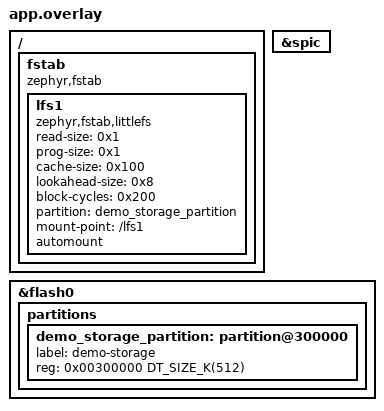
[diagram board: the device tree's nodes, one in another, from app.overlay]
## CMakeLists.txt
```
# Copyright (c) 2024 Realtek Semiconductor Corp.
# SPDX-License-Identifier: Apache-2.0

cmake_minimum_required(VERSION 3.20.0)

set(CMAKE_C_FLAGS "${CMAKE_C_FLAGS} -save-temps=obj")

find_package(Zephyr REQUIRED HINTS $ENV{ZEPHYR_BASE})
project(littlefs)

target_sources(app PRIVATE src/main.c)
```

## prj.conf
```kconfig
# 启用随机数生成器
CONFIG_TEST_RANDOM_GENERATOR=y

# LittleFS 配置
CONFIG_FILE_SYSTEM=y
CONFIG_FILE_SYSTEM_LITTLEFS=y

# 启用擦除信息统计（可选）
# CONFIG_FS_LITTLEFS_ENABLE_BLOCK_STATISTICS=y

# Flash 分区配置（根据你的设备调整）
# MUST set CONFIG_FLASH and CONFIG_FLASH_MAP manually, otherwise CONFIG_FS_LITTLEFS_FMP_DEV is not set
CONFIG_FLASH=y
CONFIG_FLASH_MAP=y
# CONFIG_FLASH_PAGE_LAYOUT=y

# 堆栈和内存配置
CONFIG_MAIN_STACK_SIZE=4096
CONFIG_HEAP_MEM_POOL_SIZE=8192

# 调试输出
# CONFIG_DEBUG=y
CONFIG_LOG=y
CONFIG_LOG_MODE_MINIMAL=y
# CONFIG_FS_LOG_LEVEL_INF=y
```

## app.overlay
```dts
/*
 * Copyright (c) 2022 Nordic Semiconductor ASA
 *
 * SPDX-License-Identifier: Apache-2.0
 */

&spic {
	status = "okay";
};

/*
&storage_partition {
  reg = <0x00250000 DT_SIZE_K(256)>;
};
*/

&flash0 {
  partitions {
    demo_storage_partition: partition@300000 {
      label = "demo-storage";
      reg = <0x00300000 DT_SIZE_K(512)>;
    };
  };
};

/ {
  fstab {
    compatible = "zephyr,fstab";
    lfs1: lfs1 {
      compatible = "zephyr,fstab,littlefs";
      read-size = < 0x1 >;
      prog-size = < 0x1 >;
      cache-size = < 0x100 >;
      lookahead-size = < 0x8 >;
      block-cycles = < 0x200 >;
      partition = <&demo_storage_partition>;
      mount-point = "/lfs1";
      automount;
    };
  };
};
```

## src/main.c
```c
/*
 * LittleFS on NOR Flash 性能测试代码
 */
#include "ameba_soc.h"

#include <zephyr/kernel.h>
#include <zephyr/fs/fs.h>
#include <zephyr/fs/littlefs.h>
#include <zephyr/storage/flash_map.h>
#include <zephyr/sys/printk.h>
#include <zephyr/random/random.h>
#include <zephyr/sys/time_units.h>
#include <string.h>
#include <stdlib.h>

/* 测试配置 */
#define TEST_PARTITION        demo_storage_partition  /* Flash 分区标签 */
#define TEST_MOUNT_POINT      "/lfs1"

#define SYNC_AFTER_WRITE (1)

#define TEST_BLOCK_SIZE_MAX     (32*1024)           /* fs_read|write API 单次读|写的 最大大小 */
#define TEST_FILE_NAME      "/lfs1/test.bin"
#define TEST_ITERATIONS     (10)

#define CHECK_READ_DATA (0) //  是否检查读出数据的有效性
#define RW_DATA_PATTREN_BASE (0xA0)
static unsigned char grw_data_pattern = 0xA0;

// 随机写的时候，速度可能小于1，而 printk 不支持打印浮点，所以放大显示
#define WRITE_SPEED_MULTIPLIER (100)

struct fs_test_config {
    uint32_t file_size_bytes;   // total file size
    uint32_t block_size_bytes;  // read/write size each time
    bool random_access;
    uint32_t rows;  // random matrix row
    uint32_t cols;  // random matrix columns

    uint32_t avg_write_speed;
    uint32_t avg_read_speed;
    uint32_t read_success_rate_x100;
    uint32_t write_success_rate_x100;
};

/* 性能统计结构体 */
struct perf_stats {
    struct fs_test_config *config;

    // 开始时，用 ms 计时，但读速度过快，ms级别精度不够，所有换成了us
    // 可以移除 ms 级别的计时
    uint64_t write_time_ms;
    uint64_t read_time_ms;

    // 最终使用的是 us 级别的计时
    uint64_t read_time_cycles;
    uint64_t write_time_cycles;
    uint64_t read_time_us;      // cycles -> us 换算得
    uint64_t write_time_us;     // cycles -> us 换算得

    uint32_t write_speed_kbps;
    uint32_t read_speed_kbps;
    uint32_t written_bytes;
    uint32_t read_bytes;

    uint32_t write_operations_completed;
    uint32_t read_operations_completed;

    bool read_success;  // true: 每次都读成功
    bool write_success; // true: 每次都写成功了
};

static uint8_t buffer[TEST_BLOCK_SIZE_MAX] __attribute__((aligned(4096)));
#if CHECK_READ_DATA
static uint8_t expected_buffer[TEST_BLOCK_SIZE_MAX];
#endif


static const uint32_t file_lengths[] = {
    4*1024,
    8*1024,
    16*1024,
    32*1024,
    64*1024,

    /* 文件 128KB时， app.overlay 中的 partition 需要 512KB, 否则随机读容易失败 */
    // 128*1024,
    };

static const uint32_t block_lengths[] = {
    128,
    256,
    512,
    1024,
    2*1024,
    4*1024,
    8*1024,
    16*1024
};

/* 全局统计 */
static struct perf_stats stats[TEST_ITERATIONS];

FS_LITTLEFS_DECLARE_DEFAULT_CONFIG(storage);
static struct fs_mount_t lfs_storage_mnt = {
    .type = FS_LITTLEFS,
    .fs_data = &storage,
    .storage_dev = (void *)FIXED_PARTITION_ID(TEST_PARTITION),
    .mnt_point = TEST_MOUNT_POINT,
};

/******************************************************************/
/******************************************************************/
#define RANDOM_COL_RANGE (1024)
#define RANDOM_ROW_RANGE (64)

// 全局变量：随机排列
uint8_t randrows[RANDOM_ROW_RANGE];  // 行的随机排列
uint16_t randcols[RANDOM_COL_RANGE];  // 列的随机排列

// 初始化随机排列
void RandomPermutationsInitialize(int M, int N) {
    if (M > RANDOM_ROW_RANGE || N > RANDOM_COL_RANGE) {
        printf("error: random row %d > %d, col %d > %d\n",
            M, RANDOM_ROW_RANGE, N, RANDOM_COL_RANGE);
        return;
    }

    // 初始化randrows数组为0到M-1
    for (int i = 0; i < M; i++) {
        randrows[i] = i;
    }
    
    // 初始化randcols数组为0到N-1
    for (int j = 0; j < N; j++) {
        randcols[j] = j;
    }
    
    // 打乱randrows数组 (Fisher-Yates洗牌算法)
    for (int i = M - 1; i > 0; i--) {
        int j = sys_rand32_get() % (i + 1);
        // 交换randrows[i]和randrows[j]
        int temp = randrows[i];
        randrows[i] = randrows[j];
        randrows[j] = temp;
    }
    
    // 打乱randcols数组 (Fisher-Yates洗牌算法)
    for (int i = N - 1; i > 0; i--) {
        int j = sys_rand32_get() % (i + 1);
        // 交换randcols[i]和randcols[j]
        int temp = randcols[i];
        randcols[i] = randcols[j];
        randcols[j] = temp;
    }

#if 0
    // 打印随机排列
    printf("rand rows [%d]: ", M);
    for (int i = 0; i < M; i++) {
        printf("%d ", randrows[i]);
    }
    printf("\n");
    
    printf("rand columns [%d]: ", N);
    for (int j = 0; j < N; j++) {
        printf("%d ", randcols[j]);
    }
    printf("\n\n");
#endif

    DCache_Clean((uint32_t)randrows, sizeof(randrows[0])*M);
    DCache_Clean((uint32_t)randcols, sizeof(randcols[0])*N);
}

static uint32_t RandomPermutationsGet(uint32_t row, uint32_t col, uint32_t columns) {
    uint32_t value = randrows[row] * columns + randcols[col];
    return value;
}


/* 打印文件系统的使用情况 */
static void print_file_system_status() {
    struct fs_statvfs stats;
    int rc = fs_statvfs(lfs_storage_mnt.mnt_point, &stats);
    if (rc < 0) {
        LOG_PRINTK("FAIL: statvfs: %d\n", rc);
        return;
    }

    LOG_PRINTK("%s: bsize = %lu ; frsize = %lu ; blocks = %lu ; bfree = %lu;"
                "total size %lu KB, available size %lu KB, used %lu KB\n",
            lfs_storage_mnt.mnt_point,
            stats.f_bsize, stats.f_frsize, stats.f_blocks, stats.f_bfree,
           stats.f_frsize * stats.f_blocks / 1024,
           stats.f_frsize * stats.f_bfree / 1024,
           (stats.f_blocks - stats.f_bfree) *stats.f_frsize / 1024
           );
}

/* 生成测试数据 */
static void generate_test_data(uint8_t *buffer, size_t size, uint8_t pattern)
{
#if CHECK_READ_DATA
    for (size_t i = 0; i < size; i++) {
        buffer[i] = (pattern + i) & 0xFF;
    }
#else
    memset(buffer, pattern&0xFF, size);
#endif

    DCache_Clean((uint32_t)buffer, size);
}

/* 测试顺序写入 */
static int test_write(struct perf_stats *stat)
{
    int rc;
    struct fs_file_t file;
    int64_t start_time, end_time;
    uint64_t start_cycles, end_cycles;

    uint32_t block_size = stat->config->block_size_bytes;  // buffer_size
    uint32_t file_size = stat->config->file_size_bytes;
    uint32_t chunk_size = -1;    // chunk size read or write each time

    /* 打开文件用于写入 */
    fs_file_t_init(&file);
    rc = fs_open(&file, TEST_FILE_NAME, FS_O_CREATE | FS_O_WRITE);
    if (rc < 0) {
        printk("Failed to open file for writing: %d\n", rc);
        return rc;
    }
    
    /* 生成测试数据 */
    generate_test_data(buffer, block_size, grw_data_pattern);
    
    /* 开始计时 */
    start_time   = k_uptime_get();
    start_cycles = k_cycle_get_64();
    
    /* 写入 */
    size_t total_written = 0;
    uint32_t offset = -1;
    int row_start = 0;
    int row = 0;
    int col  = 0;
    // DiagPrintf("\n");
    while (total_written < file_size) {
        if (stat->config->random_access) {
            offset = RandomPermutationsGet(row, col, stat->config->cols);
            offset = offset * block_size;
            // DiagPrintf("w [%d][%d] %u\n", row, col, offset);

            rc = fs_seek(&file, offset, FS_SEEK_SET);
            if (rc < 0) {
                printk("Seek failed: %d, offset %d\n", rc, offset);
                break;
            }
            // printk("rand write at offset %u\n", offset);
        }

        chunk_size = (file_size - total_written < block_size) ? file_size - total_written : block_size;
        rc = fs_write(&file, buffer, chunk_size);
        if (rc < 0 ||  rc != chunk_size) {
            printk("Write failed: expected %d, written %d; at %d\n", chunk_size, rc, total_written);
            rc = -1;
            goto out;
        }

        total_written += rc;
        stat->write_operations_completed++;
        rc = 0;

        if (stat->config->random_access) {
            row = (row + 1)% stat->config->rows;
            col++;
            if (col == stat->config->cols) {
                row_start++;
                row = row_start;
                col = 0;
            }
        }

#if CHECK_READ_DATA
        if (stat->write_operations_completed == 1) {
            printk("%u, %u, %u, %u\n", buffer[0], buffer[4], buffer[8], buffer[12]);
        }
#endif

    }

    if (stat->config->random_access) {
        printk("last write offset %d, cur_pos %d\n", offset, offset + chunk_size);
    } 

#if SYNC_AFTER_WRITE
    fs_sync(&file);
#endif

out:
    if (total_written == file_size) {
        stat->write_success = true;
    } else {
        stat->write_success = false;
    }
    stat->written_bytes = total_written;

    /* 结束计时 */
    end_time   = k_uptime_get();
    end_cycles = k_cycle_get_64();
    
    /* 记录耗时 */
    stat->write_time_cycles = end_cycles - start_cycles;
    stat->write_time_ms = end_time - start_time;

    rc = fs_close(&file);
    if (rc != 0) {
        printk("Error closing file: %d\n", rc);
    }

    return rc;
}

/* 测试顺序读取 */
static int test_read(struct perf_stats *stat)
{
    int rc;
    struct fs_file_t file;
    int64_t start_time, end_time;
    uint64_t start_cycles, end_cycles;
    uint32_t block_size = stat->config->block_size_bytes;  // buffer_size
    uint32_t file_size = stat->config->file_size_bytes;
    uint32_t chunk_size;    // chunk size read or write each time
    
    /* 打开文件用于读取 */
    fs_file_t_init(&file);
    rc = fs_open(&file, TEST_FILE_NAME, FS_O_READ);
    if (rc < 0) {
        printk("Failed to open file for reading: %d\n", rc);
        return rc;
    }

#if CHECK_READ_DATA
    /* 生成预期数据 */
    generate_test_data(expected_buffer, block_size, grw_data_pattern);
#endif

    /* 开始计时 */
    start_time   = k_uptime_get();
    start_cycles = k_cycle_get_64();
    
    /* 读取并验证 */
    uint32_t offset;
    int row_start = 0;
    int row = 0;
    int col  = 0;
    size_t total_read = 0;
    while (total_read < file_size) {
        if (stat->config->random_access) {
            offset = RandomPermutationsGet(row, col, stat->config->cols);
            offset = offset * block_size;

            // DiagPrintf("r [%d] [%d] %u\n", row, col, offset);

            rc = fs_seek(&file, offset, FS_SEEK_SET);
            if (rc < 0) {
                printk("Seek failed: %d, offset %d\n", rc, offset);
                break;
            }
            // printk("rand read at offset %u\n", offset);
        }

        chunk_size = (file_size - total_read < block_size) ? file_size - total_read : block_size;
        rc = fs_read(&file, buffer, chunk_size);
        if (rc < 0 || rc != chunk_size) {
            printk("Read failed: expected %d, read %d; at %d\n", chunk_size, rc, total_read);
            rc = -1;
            goto out;
        }

        total_read += rc;
        stat->read_operations_completed++;

        if (stat->config->random_access) {
            row = (row + 1)% stat->config->rows;
            col++;
            if (col == stat->config->cols) {
                row_start++;
                row = row_start;
                col = 0;
            }
        }

#if CHECK_READ_DATA
if (stat->read_operations_completed == 1) {
            printk("%u, %u, %u, %u\n", buffer[0], buffer[4], buffer[8], buffer[12]);
        }

        /* 验证数据完整性 */
        if (memcmp(buffer, expected_buffer, rc) != 0) {
            printk("ERROR: Data verification failed at offset %zu\n", total_read);
            fs_close(&file);
            return -1;
        }
#endif


        rc = 0;
    }

out:
    if (total_read == file_size) {
        stat->read_success = true;
    } else {
        stat->read_success = false;
    }
    stat->read_bytes = total_read;

    /* 结束计时 */
    end_time   = k_uptime_get();
    end_cycles = k_cycle_get_64();
    
    /* 计算耗时*/
    stat->read_time_cycles = end_cycles - start_cycles;
    stat->read_time_ms = (end_time - start_time);

    fs_close(&file);
    return rc;
}

/* 显示性能结果 */
static void display_performance_results(struct fs_test_config *config, struct perf_stats *stats)
{
    printk("\n====== LittleFS Performance Results ======\n");
    printk("file_size %d bytes, block_size %d bytes, random access %d. "
            "Average read speed %d KB/s. Average write speed %u.%.2u KB/s. "
            "ReadSuccessRate %u%%, WriteSuccessRate %u%%\n", 
        config->file_size_bytes, config->block_size_bytes, config->random_access, 
        config->avg_read_speed, config->avg_write_speed / WRITE_SPEED_MULTIPLIER, config->avg_write_speed % WRITE_SPEED_MULTIPLIER,
        config->read_success_rate_x100, config->write_success_rate_x100);

    for (int i = 0; i < TEST_ITERATIONS; i++) {
        struct perf_stats *stat = &stats[i];
        printk("[%d] WriteSuccess %d, Completed Operations %u; ReadSuccess %d, Completed Operations %u\n",
            i, stat->write_success, stat->write_operations_completed, stat->read_success, stat->read_operations_completed);
        printk("[%d] Sequential Write: %llu ms, %llu us, %u.%.2u KB/s\n", 
            i, stat->write_time_ms, stat->write_time_us,
            stat->write_speed_kbps / WRITE_SPEED_MULTIPLIER, stat->write_speed_kbps % WRITE_SPEED_MULTIPLIER);
        printk("[%d] Sequential Read:  %llu ms, %llu us, %u KB/s.\n", 
            i, stat->read_time_ms, stat->read_time_us, stat->read_speed_kbps);

    }
    printk("======================================\n\n");
}

/* 主测试函数 */
int main(void) {
    int rc;
    printk("\n***** LittleFS on NOR Flash Performance Test *****\n");
    uint64_t cycles_per_sec = sys_clock_hw_cycles_per_sec();
    printk("cycles_per_sec=%llu\n", cycles_per_sec);

    print_file_system_status();

    // 清理测试文件，确保测试环境重置
    (void)fs_unlink(TEST_FILE_NAME);

    print_file_system_status();

    int total_cases = 2*ARRAY_SIZE(block_lengths)*ARRAY_SIZE(file_lengths);
    int case_number = 0;
    struct fs_test_config test_config;
    for (int random = 0; random < 2; random++) {
        for (size_t block = 0; block < ARRAY_SIZE(block_lengths); block++) {
            for (size_t flen = 0; flen < ARRAY_SIZE(file_lengths); flen++) {
                // 设置测试参数
                memset(&test_config, 0, sizeof(struct fs_test_config));
                test_config.file_size_bytes =  file_lengths[flen];
                test_config.block_size_bytes = block_lengths[block];
                test_config.random_access = random;
                case_number++;

                struct fs_test_config *config = &test_config;
                if ((config->block_size_bytes > config->file_size_bytes) 
                    // || (config->random_access && config->file_size_bytes > 16*1024)

                    /* fs_write len 很小时，随机写的速度很慢，跳过*/
                    || (config->random_access && config->block_size_bytes < 512
                    )
                    ) {
                    printk("skip: [%d:%d] file %u bytes, block %u bytes, random access %d\n",
                        case_number, total_cases,
                        config->file_size_bytes, config->block_size_bytes, config->random_access);
                    continue;
                }

                if (config->block_size_bytes > TEST_BLOCK_SIZE_MAX) {
                    printk("ERROR: block_size %d exceeds %d\n", config->block_size_bytes, TEST_BLOCK_SIZE_MAX);
                    continue;
                }

                printk("test: [%d:%d] file %d bytes, block %d bytes, random access %d\n", 
                    case_number, total_cases,
                    config->file_size_bytes, config->block_size_bytes, config->random_access);

                /* 预生成 随机序列 */
                int blocks = config->file_size_bytes/config->block_size_bytes;
                if (blocks > RANDOM_COL_RANGE) {
                    config->cols = RANDOM_COL_RANGE;
                    config->rows = blocks/RANDOM_COL_RANGE;
                } else {
                    config->rows = 1;
                    config->cols = blocks;
                }
                if (config->rows * config->cols != blocks || config->rows > RANDOM_ROW_RANGE) {
                    printk("ERROR: rows %d, cols %d, blocks %d\n", config->rows, config->cols, blocks);
                    continue;
                }

                RandomPermutationsInitialize(config->rows, config->cols);

                memset(stats, 0, sizeof(stats[0]) * TEST_ITERATIONS);
                for (int i = 0; i < TEST_ITERATIONS; i++) {
                    grw_data_pattern = RW_DATA_PATTREN_BASE + i;
                    (void)fs_unlink(TEST_FILE_NAME);
                    struct perf_stats *stat = &stats[i];
                    stat->config = config;

                    printk("iteration: %d:%d\n", i, TEST_ITERATIONS);
                    /* 测试1: 顺序写入 */
                    // print_file_system_status();
                    printk("Test 1: write test...\n");
                    DCache_CleanInvalidate(0xFFFFFFFF, 0xFFFFFFFF);
                    rc = test_write(stat);
                    if (rc != 0) {
                        printk("[%d] Sequential write test failed: %d\n", i, rc);
                        // return rc;
                    }

                    /* 测试2: 顺序读取 */
                    // print_file_system_status();
                    printk("Test 2: read test...\n");
                    DCache_CleanInvalidate(0xFFFFFFFF, 0xFFFFFFFF);
                    rc = test_read(stat);
                    if (rc != 0) {
                        printk("[%d] Sequential read test failed: %d\n", i, rc);
                        // return rc;
                    }
                }

                /* 计算均值, 只有成功的 iteration 参与均值计算，
                    以防在 pos=0 处失败时，read_bytes或written_bytes 为0，导致计算的速度为0*/
                uint32_t total_read_speed = 0;
                uint32_t total_write_speed = 0;
                uint32_t read_success_times = 0;
                uint32_t write_success_times = 0;
                for (int i = 0; i < TEST_ITERATIONS; i++) {
                    struct perf_stats *stat = &stats[i];

                    stat->read_time_us = (stat->read_time_cycles * 1000000ULL) / cycles_per_sec;
                    stat->write_time_us = (stat->write_time_cycles * 1000000ULL) / cycles_per_sec;
                    stat->read_speed_kbps = (int)(((float)stat->read_bytes / 1024 * cycles_per_sec) / stat->read_time_cycles);
                    stat->write_speed_kbps = (int)(((float)stat->written_bytes / 1024 * cycles_per_sec * WRITE_SPEED_MULTIPLIER) / stat->write_time_cycles);

                    if (stat->read_success) {
                        read_success_times++;
                        total_read_speed += stat->read_speed_kbps;
                    }
                    if (stat->write_success) {
                        write_success_times++;
                        total_write_speed += stat->write_speed_kbps;
                    }
                }

                if (read_success_times > 0) {
                    config->avg_read_speed = total_read_speed / read_success_times;
                } else {
                    config->avg_read_speed = -1;
                }

                if (write_success_times > 0) {
                    config->avg_write_speed = total_write_speed / write_success_times;
                } else {
                    config->avg_write_speed = -1;
                }

                config->read_success_rate_x100  = read_success_times * 100 / TEST_ITERATIONS;
                config->write_success_rate_x100 = write_success_times * 100 / TEST_ITERATIONS;

                /* 显示结果 */
                display_performance_results(config, stats);
            }
        }
    }

    printk("\n***** Finish LittleFS on NOR Flash Performance Test *****\n");

    return 0;
}
```

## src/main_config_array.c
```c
/*
 * LittleFS on NOR Flash 性能测试代码
 */

#include <zephyr/kernel.h>
#include <zephyr/fs/fs.h>
#include <zephyr/fs/littlefs.h>
#include <zephyr/storage/flash_map.h>
#include <zephyr/sys/printk.h>
#include <zephyr/random/random.h>
#include <zephyr/sys/time_units.h>
#include <string.h>
#include <stdlib.h>

/* 测试配置 */
#define TEST_PARTITION        storage_partition  /* Flash 分区标签 */
#define TEST_MOUNT_POINT      "/lfs1"

/* 测试配置 */
#define TEST_BLOCK_SIZE_MAX     (32*1024)           /* 测试块最大大小 */
#define TEST_FILE_NAME      "/lfs1/test.bin"
#define TEST_ITERATIONS     (10)

#define CHECK_READ_DATA (0) //  是否检查读出数据的有效性
#define RW_DATA_PATTREN (0xA5)

// 随机写的时候，速度可能小于1，而 printk 不支持打印浮点，所以放大显示
#define WRITE_SPEED_MULTIPLIER (100)

struct fs_test_config {
    uint32_t file_size_bytes;   // total file size
    uint32_t block_size_bytes;  // read/write size each time
    bool random_access;

    uint32_t avg_write_speed;
    uint32_t avg_read_speed;
    uint32_t read_success_rate_x100;
    uint32_t write_success_rate_x100;
};

/* 性能统计结构体 */
struct perf_stats {
    struct fs_test_config *config;
    uint64_t write_time_ms;
    uint64_t read_time_ms;
    uint64_t read_time_cycles;
    uint64_t write_time_cycles;
    uint32_t write_operations_completed;
    uint32_t read_operations_completed;

    uint64_t read_time_us;
    uint64_t write_time_us;
    uint32_t write_speed_kbps;
    uint32_t read_speed_kbps;
    uint32_t written_bytes;
    uint32_t read_bytes;
    bool read_success;  // true: 每次都读成功
    bool write_success; // true: 每次都写成功了
};

static uint8_t buffer[TEST_BLOCK_SIZE_MAX] __attribute__((aligned(4096)));
#if CHECK_READ_DATA
static uint8_t expected_buffer[TEST_BLOCK_SIZE_MAX];
#endif

/* 全局统计 */
static struct perf_stats stats[TEST_ITERATIONS];

static struct fs_test_config configs[] = {
    // {4*1024, 128, 1},
    // {64*1024, 4*1024, 0},

#if 1
    { 4*1024,     64, 0},
    { 4*1024,    128, 0},
    { 4*1024,    256, 0},
    { 4*1024,    512, 0},
    { 4*1024,   1024, 0},
    { 4*1024, 2*1024, 0},
    { 4*1024, 4*1024, 0},
      
    { 8*1024,     64, 0},
    { 8*1024,    128, 0},
    { 8*1024,    256, 0},
    { 8*1024,    512, 0},
    { 8*1024,   1024, 0},
    { 8*1024, 2*1024, 0},
    { 8*1024, 4*1024, 0},
      
    {16*1024,     64, 0},
    {16*1024,    128, 0},
    {16*1024,    256, 0},
    {16*1024,    512, 0},
    {16*1024,   1024, 0},
    {16*1024, 2*1024, 0},
    {16*1024, 4*1024, 0},
    
    {32*1024,     64, 0},
    {32*1024,    128, 0},
    {32*1024,    256, 0},
    {32*1024,    512, 0},
    {32*1024,   1024, 0},
    {32*1024, 2*1024, 0},
    {32*1024, 4*1024, 0},

    {64*1024,     64, 0},
    {64*1024,    128, 0},
    {64*1024,    256, 0},
    {64*1024,    512, 0},
    {64*1024,   1024, 0},
    {64*1024, 2*1024, 0},
    {64*1024, 4*1024, 0},

// random access
    { 4*1024,     64, 1},
    { 4*1024,    128, 1},
    { 4*1024,    256, 1},
    { 4*1024,    512, 1},
    { 4*1024,   1024, 1},
    { 4*1024, 2*1024, 1},
    { 4*1024, 4*1024, 1},
    { 8*1024,     64, 1},
    { 8*1024,    128, 1},
    { 8*1024,    256, 1},
    { 8*1024,    512, 1},
    { 8*1024,   1024, 1},
    { 8*1024, 2*1024, 1},
    { 8*1024, 4*1024, 1},
    {16*1024,     64, 1},
    {16*1024,    128, 1},
    {16*1024,    256, 1},
    {16*1024,    512, 1},
    {16*1024,   1024, 1},
    {16*1024, 2*1024, 1},
    {16*1024, 4*1024, 1},
    {32*1024,     64, 1},
    {32*1024,    128, 1},
    {32*1024,    256, 1},
    {32*1024,    512, 1},
    {32*1024,   1024, 1},
    {32*1024, 2*1024, 1},
    {32*1024, 4*1024, 1},
    {64*1024,     64, 1},
    {64*1024,    128, 1},
    {64*1024,    256, 1},
    {64*1024,    512, 1},
    {64*1024,   1024, 1},
    {64*1024, 2*1024, 1},
    {64*1024, 4*1024, 1},
#endif
};

FS_LITTLEFS_DECLARE_DEFAULT_CONFIG(storage);
static struct fs_mount_t lfs_storage_mnt = {
    .type = FS_LITTLEFS,
    .fs_data = &storage,
    .storage_dev = (void *)FIXED_PARTITION_ID(TEST_PARTITION),
    .mnt_point = TEST_MOUNT_POINT,
};

/******************************************************************/
/* 打印文件系统的使用情况 */
static void print_file_system_status() {
    struct fs_statvfs stats;
    int rc = fs_statvfs(lfs_storage_mnt.mnt_point, &stats);
    if (rc < 0) {
        LOG_PRINTK("FAIL: statvfs: %d\n", rc);
        return;
    }

    LOG_PRINTK("%s: bsize = %lu ; frsize = %lu ; blocks = %lu ; bfree = %lu;"
                "total size %lu KB, available size %lu KB, used %lu KB\n",
            lfs_storage_mnt.mnt_point,
            stats.f_bsize, stats.f_frsize, stats.f_blocks, stats.f_bfree,
           stats.f_frsize * stats.f_blocks / 1024,
           stats.f_frsize * stats.f_bfree / 1024,
           (stats.f_blocks - stats.f_bfree) *stats.f_frsize / 1024
           );
}

/* 生成测试数据 */
static void generate_test_data(uint8_t *buffer, size_t size, uint8_t pattern)
{
#if CHECK_READ_DATA
    for (size_t i = 0; i < size; i++) {
        buffer[i] = (pattern + i) & 0xFF;
    }
#else
    memset(buffer, pattern&0xFF, size);
#endif
}

/* 测试顺序写入 */
static int test_sequential_write(struct perf_stats *stat)
{
    int rc;
    struct fs_file_t file;
    int64_t start_time, end_time;
    uint64_t start_cycles, end_cycles;

    uint32_t block_size = stat->config->block_size_bytes;  // buffer_size
    uint32_t file_size = stat->config->file_size_bytes;
    uint32_t chunk_size;    // chunk size read or write each time

    /* 打开文件用于写入 */
    fs_file_t_init(&file);
    rc = fs_open(&file, TEST_FILE_NAME, FS_O_CREATE | FS_O_WRITE);
    if (rc < 0) {
        printk("Failed to open file for writing: %d\n", rc);
        return rc;
    }
    
    /* 生成测试数据 */
    generate_test_data(buffer, block_size, RW_DATA_PATTREN);
    
    /* 开始计时 */
    start_time   = k_uptime_get();
    start_cycles = k_cycle_get_64();
    
    /* 写入 */
    size_t total_written = 0;
    while (total_written < file_size) {
        if (stat->config->random_access) {
            uint32_t offset = sys_rand32_get() % (file_size/block_size) * block_size;
            rc = fs_seek(&file, offset, FS_SEEK_SET);
            if (rc < 0) {
                printk("Seek failed: %d, offset %d\n", rc, offset);
                break;
            }
            // printk("rand write at offset %u\n", offset);
        }

        chunk_size = (file_size - total_written < block_size) ? file_size - total_written : block_size;
        rc = fs_write(&file, buffer, chunk_size);
        if (rc < 0 ||  rc != chunk_size) {
            printk("Write failed: expected %d, written %d; at %d\n", chunk_size, rc, total_written);
            rc = -1;
            goto out;
        }

        total_written += rc;
        stat->write_operations_completed++;
    }

out:
    if (total_written == file_size) {
        stat->write_success = true;
    } else {
        stat->write_success = false;
    }
    stat->written_bytes = total_written;

    /* 结束计时 */
    end_time   = k_uptime_get();
    end_cycles = k_cycle_get_64();
    
    /* 记录耗时 */
    stat->write_time_cycles = end_cycles - start_cycles;
    stat->write_time_ms = end_time - start_time;

    rc = fs_close(&file);
    if (rc != 0) {
        printk("Error closing file: %d\n", rc);
    }

    return rc;
}

/* 测试顺序读取 */
static int test_sequential_read(struct perf_stats *stat)
{
    int rc;
    struct fs_file_t file;
    int64_t start_time, end_time;
    uint64_t start_cycles, end_cycles;
    uint32_t block_size = stat->config->block_size_bytes;  // buffer_size
    uint32_t file_size = stat->config->file_size_bytes;
    uint32_t chunk_size;    // chunk size read or write each time
    
    /* 打开文件用于读取 */
    fs_file_t_init(&file);
    rc = fs_open(&file, TEST_FILE_NAME, FS_O_READ);
    if (rc < 0) {
        printk("Failed to open file for reading: %d\n", rc);
        return rc;
    }

#if CHECK_READ_DATA
    /* 生成预期数据 */
    generate_test_data(expected_buffer, block_size, RW_DATA_PATTREN);
#endif

    /* 开始计时 */
    start_time   = k_uptime_get();
    start_cycles = k_cycle_get_64();
    
    /* 读取并验证 */
    size_t total_read = 0;
    while (total_read < file_size) {
        if (stat->config->random_access) {
            uint32_t offset = sys_rand32_get() % (file_size/block_size) * block_size;
            rc = fs_seek(&file, offset, FS_SEEK_SET);
            if (rc < 0) {
                printk("Seek failed: %d, offset %d\n", rc, offset);
                break;
            }
            // printk("rand read at offset %u\n", offset);
        }

        chunk_size = (file_size - total_read < block_size) ? file_size - total_read : block_size;
        rc = fs_read(&file, buffer, chunk_size);
        if (rc < 0 || rc != chunk_size) {
            printk("Read failed: expected %d, read %d; at %d\n", chunk_size, rc, total_read);
            rc = -1;
            goto out;
        }

#if CHECK_READ_DATA
        /* 验证数据完整性 */
        if (memcmp(buffer, expected_buffer, rc) != 0) {
            printk("ERROR: Data verification failed at offset %zu\n", total_read);
            fs_close(&file);
            return -1;
        }
#endif

        total_read += rc;
        stat->read_operations_completed++;
    }

out:
    if (total_read == file_size) {
        stat->read_success = true;
    } else {
        stat->read_success = false;
    }
    stat->read_bytes = total_read;

    /* 结束计时 */
    end_time   = k_uptime_get();
    end_cycles = k_cycle_get_64();
    
    /* 计算耗时*/
    stat->read_time_cycles = end_cycles - start_cycles;
    stat->read_time_ms = (end_time - start_time);

    fs_close(&file);
    return rc;
}

/* 显示性能结果 */
static void display_performance_results(struct fs_test_config *config, struct perf_stats *stats)
{
    printk("\n====== LittleFS Performance Results ======\n");
    printk("file_size %d bytes, block_size %d bytes, random access %d. Average read speed %d KB/s. Average write speed %u.%.2u KB/s. ReadSuccessRate %u%%, WriteSuccessRate%u%%\n", 
        config->file_size_bytes, config->block_size_bytes, config->random_access, 
        config->avg_read_speed, config->avg_write_speed / WRITE_SPEED_MULTIPLIER, config->avg_write_speed % WRITE_SPEED_MULTIPLIER,
        config->read_success_rate_x100, config->write_success_rate_x100);

    for (int i = 0; i < TEST_ITERATIONS; i++) {
        struct perf_stats *stat = &stats[i];
        printk("[%d] WriteSuccess %d, Completed Operations %u; WriteSuccess %d, Completed Operations %u\n",
            i, stat->write_success, stat->write_operations_completed, stat->read_success, stat->read_operations_completed);
        printk("[%d] Sequential Write: %llu ms, %llu us, %u.%.2u KB/s\n", 
            i, stat->write_time_ms, stat->write_time_us,
            stat->write_speed_kbps / WRITE_SPEED_MULTIPLIER, stat->write_speed_kbps % WRITE_SPEED_MULTIPLIER);
        printk("[%d] Sequential Read:  %llu ms, %llu us, %u KB/s.\n", 
            i, stat->read_time_ms, stat->read_time_us, stat->read_speed_kbps);

    }
    printk("======================================\n");
}

/* 主测试函数 */
int main(void) {
    int rc;
    printk("\n***** LittleFS on NOR Flash Performance Test *****\n");
    uint64_t cycles_per_sec = sys_clock_hw_cycles_per_sec();
    printk("cycles_per_sec=%llu\n", cycles_per_sec);

    print_file_system_status();

    // 清理测试文件，确保测试环境重置
    (void)fs_unlink(TEST_FILE_NAME);

    print_file_system_status();

    int config_nums = (sizeof(configs) / sizeof(configs[0]));
    for (int c = 0; c < config_nums; c++) {
        struct fs_test_config *config = &configs[c];
        if (config->block_size_bytes > TEST_BLOCK_SIZE_MAX) {
            printk("ERROR: block_size %d exceeds %d\n", config->block_size_bytes, TEST_BLOCK_SIZE_MAX);
            continue;
        }
        printk("test [%d:%d] file_size %d bytes, block_size %d bytes, random access %d\n", 
            c, config_nums,
            config->file_size_bytes, config->block_size_bytes, config->random_access);

        memset(stats, 0, sizeof(stats[0]) * TEST_ITERATIONS);
        for (int i = 0; i < TEST_ITERATIONS; i++) {
            (void)fs_unlink(TEST_FILE_NAME);
            struct perf_stats *stat = &stats[i];
            stat->config = config;

            /* 测试1: 顺序写入 */
            // print_file_system_status();
            // printk("Test 1: Sequential write test...\n");
            rc = test_sequential_write(stat);
            if (rc != 0) {
                printk("[%d] Sequential write test failed: %d\n", i, rc);
                return rc;
            }

            /* 测试2: 顺序读取 */
            // print_file_system_status();
            // printk("Test 2: Sequential read test...\n");
            rc = test_sequential_read(stat);
            if (rc != 0) {
                printk("[%d] Sequential read test failed: %d\n", i, rc);
                return rc;
            }

        }

        /* 计算均值 */
        uint32_t total_read_speed = 0;
        uint32_t total_write_speed = 0;
        uint32_t read_success_times = 0;
        uint32_t write_success_times = 0;
        for (int i = 0; i < TEST_ITERATIONS; i++) {
            struct perf_stats *stat = &stats[i];

            stat->read_time_us = (stat->read_time_cycles * 1000000ULL) / cycles_per_sec;
            stat->write_time_us = (stat->write_time_cycles * 1000000ULL) / cycles_per_sec;
            stat->read_speed_kbps = (int)(((float)stat->read_bytes / 1024 * cycles_per_sec) / stat->read_time_cycles);
            stat->write_speed_kbps = (int)(((float)stat->written_bytes / 1024 * cycles_per_sec * WRITE_SPEED_MULTIPLIER) / stat->write_time_cycles);

            total_read_speed += stat->read_speed_kbps;
            total_write_speed += stat->write_speed_kbps;

            if (stat->read_success) {
                read_success_times++;
            }
            if (stat->write_success) {
                write_success_times++;
            }
        }
        config->avg_read_speed  = total_read_speed / TEST_ITERATIONS;
        config->avg_write_speed = total_write_speed / TEST_ITERATIONS;
        config->read_success_rate_x100 = read_success_times*100/(config->file_size_bytes/config->block_size_bytes);
        config->write_success_rate_x100 = write_success_times*100/(config->file_size_bytes/config->block_size_bytes);

        /* 显示结果 */
        display_performance_results(config, stats);

    }

    return 0;
}
```

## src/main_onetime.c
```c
/*
 * LittleFS 性能测试代码
 * 针对 NOR Flash 特性优化
 */

#include <zephyr/kernel.h>
#include <zephyr/fs/fs.h>
#include <zephyr/fs/littlefs.h>
#include <zephyr/storage/flash_map.h>
#include <zephyr/sys/printk.h>
#include <string.h>
#include <stdlib.h>

/* 测试配置 */
#define TEST_PARTITION        storage_partition  /* Flash 分区标签 */
#define TEST_MOUNT_POINT      "/lfs1"
#define TEST_BLOCK_SIZE       4096              /* 匹配 Flash 擦除块大小 */
#define TEST_FILE_SIZE        (64 * 1024)       /* 64KB 测试文件 */
#define TEST_ITERATIONS       100
#define TEST_SMALL_FILE_COUNT 100

/* 性能统计结构 */
struct lfs_perf_stats {
    uint64_t seq_write_time;
    uint64_t seq_read_time;
    uint64_t random_write_time;
    uint64_t random_read_time;
    uint32_t write_speed;
    uint32_t read_speed;
    uint32_t operations;
    uint32_t erase_cycles;
};

/* 测试状态 */
static struct lfs_perf_stats stats;
FS_LITTLEFS_DECLARE_DEFAULT_CONFIG(storage);
static struct fs_mount_t lfs_storage_mnt = {
    .type = FS_LITTLEFS,
    .fs_data = &storage,
    .storage_dev = (void *)FIXED_PARTITION_ID(TEST_PARTITION),
    .mnt_point = TEST_MOUNT_POINT,
};

/* 生成测试数据（模式化，便于验证） */
static void generate_pattern_data(uint8_t *buf, size_t len, uint32_t seed) {
    for (size_t i = 0; i < len; i++) {
        buf[i] = (seed + i) & 0xFF;
    }
}

/* 验证数据完整性 */
static int verify_pattern_data(const uint8_t *buf, size_t len, uint32_t seed) {
    for (size_t i = 0; i < len; i++) {
        if (buf[i] != ((seed + i) & 0xFF)) {
            printk("数据验证失败 @ offset %zu: 预期 0x%02x, 实际 0x%02x\n",
                   i, (seed + i) & 0xFF, buf[i]);
            return -1;
        }
    }
    return 0;
}

static void print_fs_status() {
    struct fs_statvfs stats;
    int rc = fs_statvfs(lfs_storage_mnt.mnt_point, &stats);
	if (rc < 0) {
		LOG_PRINTK("FAIL: statvfs: %d\n", rc);
		return;
	}

	LOG_PRINTK("%s: bsize = %lu ; frsize = %lu ; blocks = %lu ; bfree = %lu;"
                "total size %lu KB, available size %lu KB, used %lu KB\n",
		   lfs_storage_mnt.mnt_point,
		   stats.f_bsize, stats.f_frsize, stats.f_blocks, stats.f_bfree,
           stats.f_frsize * stats.f_blocks / 1024,
           stats.f_frsize * stats.f_bfree / 1024,
           (stats.f_blocks - stats.f_bfree) *stats.f_frsize / 1024
           );
}

/* 场景1：基础顺序读写测试 */
static int test_sequential_rw(void) {
    char filename[32];
    struct fs_file_t file;
    uint8_t *buffer;
    int rc;
    int64_t start_time, end_time;
    
    snprintf(filename, sizeof(filename), "%s/seq_test.bin", TEST_MOUNT_POINT);
    
    /* 分配对齐的缓冲区（重要！） */
    buffer = k_malloc(TEST_BLOCK_SIZE);
    if (!buffer) {
        printk("内存分配失败\n");
        return -ENOMEM;
    }
    
    fs_file_t_init(&file);
    
    /* === 顺序写入测试 === */
    printk("开始顺序写入测试...\n");
    rc = fs_open(&file, filename, FS_O_CREATE | FS_O_WRITE);
    if (rc < 0) {
        printk("无法创建文件: %d\n", rc);
        goto cleanup;
    }
    
    generate_pattern_data(buffer, TEST_BLOCK_SIZE, 0xAA);
    start_time = k_uptime_get();
    
    size_t total_written = 0;
    while (total_written < TEST_FILE_SIZE) {
        rc = fs_write(&file, buffer, TEST_BLOCK_SIZE);
        if (rc < 0) {
            printk("写入失败: %d\n", rc);
            break;
        }
        total_written += rc;
        stats.operations++;
    }
    
    end_time = k_uptime_get();
    stats.seq_write_time = (end_time - start_time);
    fs_close(&file);
    
    if (total_written < TEST_FILE_SIZE) {
        rc = -EIO;
        goto cleanup;
    }
    
    printk("顺序写入: %zu bytes, %llu ms\n", total_written, stats.seq_write_time);
    print_fs_status();

    /* === 顺序读取测试 === */
    printk("开始顺序读取测试...\n");
    rc = fs_open(&file, filename, FS_O_READ);
    if (rc < 0) {
        printk("无法打开文件: %d\n", rc);
        goto cleanup;
    }
    
    start_time = k_uptime_get();
    size_t total_read = 0;
    while (total_read < TEST_FILE_SIZE) {
        rc = fs_read(&file, buffer, TEST_BLOCK_SIZE);
        if (rc < 0) {
            printk("读取失败: %d\n", rc);
            break;
        }
        
        // 验证数据
        if (verify_pattern_data(buffer, rc, 0xAA) < 0) {
            rc = -EIO;
            break;
        }
        
        total_read += rc;
    }
    
    end_time = k_uptime_get();
    stats.seq_read_time = (end_time - start_time);
    fs_close(&file);
    
    printk("顺序读取: %zu bytes, %llu ms\n", total_read, stats.seq_read_time);
    print_fs_status();

    // 计算速度
    stats.write_speed = (TEST_FILE_SIZE / 1024 * 1000) / stats.seq_write_time;
    stats.read_speed  = (TEST_FILE_SIZE / 1024 * 1000) / stats.seq_read_time;
    
    rc = 0;
    
cleanup:
    fs_unlink(filename);
    k_free(buffer);
    return rc;
}

/* 场景2：随机访问测试（NOR Flash 关键测试） */
static int test_random_access(void) {
    char filename[32];
    struct fs_file_t file;
    uint8_t *write_buf, *read_buf;
    int rc;
    int64_t total_time = 0;
    const int iterations = 100;
    
    snprintf(filename, sizeof(filename), "%s/random_test.bin", TEST_MOUNT_POINT);
    
    write_buf = k_malloc(TEST_BLOCK_SIZE);
    read_buf = k_malloc(TEST_BLOCK_SIZE);
    if (!write_buf || !read_buf) {
        rc = -ENOMEM;
        goto cleanup;
    }
    
    /* 先创建一个基础文件 */
    fs_file_t_init(&file);
    rc = fs_open(&file, filename, FS_O_CREATE | FS_O_WRITE);
    if (rc < 0) {
        printk("无法创建文件: %d\n", rc);
        goto cleanup;
    }
    
    // 用零填充文件
    memset(write_buf, 0, TEST_BLOCK_SIZE);
    for (int i = 0; i < 16; i++) {
        fs_write(&file, write_buf, TEST_BLOCK_SIZE);
    }
    fs_close(&file);
    
    /* 随机访问测试 */
    printk("开始随机访问测试 (%d 次迭代)...\n", iterations);
    
    for (int i = 0; i < iterations; i++) {
        // 生成随机偏移（块对齐）
        off_t offset = (i * 997) % (16 * TEST_BLOCK_SIZE - TEST_BLOCK_SIZE);
        offset = (offset / TEST_BLOCK_SIZE) * TEST_BLOCK_SIZE;
        
        // 生成随机数据
        generate_pattern_data(write_buf, TEST_BLOCK_SIZE, i);
        
        // 打开文件进行读写
        rc = fs_open(&file, filename, FS_O_RDWR);
        if (rc < 0) {
            printk("无法打开文件: %d\n", rc);
            break;
        }
        
        int64_t start_time = k_uptime_get();
        
        // 定位并写入
        rc = fs_seek(&file, offset, FS_SEEK_SET);
        if (rc < 0) {
            printk("定位失败: %d\n", rc);
            fs_close(&file);
            break;
        }
        
        rc = fs_write(&file, write_buf, TEST_BLOCK_SIZE);
        if (rc < 0) {
            printk("随机写入失败: %d\n", rc);
            fs_close(&file);
            break;
        }
        
        // 重新定位并读取验证
        rc = fs_seek(&file, offset, FS_SEEK_SET);
        if (rc < 0) {
            printk("定位失败: %d\n", rc);
            fs_close(&file);
            break;
        }
        
        rc = fs_read(&file, read_buf, TEST_BLOCK_SIZE);
        if (rc < 0) {
            printk("随机读取失败: %d\n", rc);
            fs_close(&file);
            break;
        }
        
        // 验证数据
        if (memcmp(write_buf, read_buf, TEST_BLOCK_SIZE) != 0) {
            printk("数据不匹配 @ 迭代 %d\n", i);
            fs_close(&file);
            rc = -EIO;
            break;
        }
        
        int64_t end_time = k_uptime_get();
        total_time += (end_time - start_time);
        
        fs_close(&file);
        stats.operations++;
        
        if ((i + 1) % 20 == 0) {
            printk("  完成 %d/%d 次随机操作\n", i + 1, iterations);
        }
    }
    
    stats.random_write_time = total_time * 1000 / iterations; // 平均微秒
    
    printk("随机访问测试完成，平均 %llu us/操作\n", stats.random_write_time);
    
cleanup:
    fs_unlink(filename);
    k_free(write_buf);
    k_free(read_buf);
    return rc;
}

/* 场景3：小文件密集型操作 */
static int test_small_files(void) {
    char filename[32];
    struct fs_file_t file;
    uint8_t buffer[256];
    int rc;
    int64_t start_time, end_time;
    int success_count = 0;
    
    printk("开始小文件测试 (%d 个文件)...\n", TEST_SMALL_FILE_COUNT);
    
    start_time = k_uptime_get();
    
    /* 创建大量小文件 */
    for (int i = 0; i < TEST_SMALL_FILE_COUNT; i++) {
        snprintf(filename, sizeof(filename), "%s/small_%04d.txt", 
                 TEST_MOUNT_POINT, i);
        
        fs_file_t_init(&file);
        rc = fs_open(&file, filename, FS_O_CREATE | FS_O_WRITE);
        if (rc < 0) {
            printk("无法创建文件 %s: %d\n", filename, rc);
            continue;
        }
        
        // 写入少量数据
        snprintf((char *)buffer, sizeof(buffer), 
                "小文件测试 #%d, 时间戳: %lld\n", i, k_uptime_get());
        rc = fs_write(&file, buffer, strlen((char *)buffer));
        fs_close(&file);
        
        if (rc >= 0) {
            success_count++;
        }
        
        stats.operations++;
    }
    
    end_time = k_uptime_get();
    printk("创建 %d 个小文件耗时: %lld ms\n", 
           success_count, end_time - start_time);
    
    /* 读取并验证小文件 */
    start_time = k_uptime_get();
    int verify_count = 0;
    
    for (int i = 0; i < TEST_SMALL_FILE_COUNT; i++) {
        snprintf(filename, sizeof(filename), "%s/small_%04d.txt", 
                 TEST_MOUNT_POINT, i);
        
        fs_file_t_init(&file);
        rc = fs_open(&file, filename, FS_O_READ);
        if (rc < 0) {
            continue; // 文件可能创建失败
        }
        
        rc = fs_read(&file, buffer, sizeof(buffer));
        fs_close(&file);
        
        if (rc > 0) {
            verify_count++;
        }
    }
    
    end_time = k_uptime_get();
    printk("读取 %d 个小文件耗时: %lld ms\n", 
           verify_count, end_time - start_time);
    
    /* 删除小文件 */
    start_time = k_uptime_get();
    int delete_count = 0;
    
    for (int i = 0; i < TEST_SMALL_FILE_COUNT; i++) {
        snprintf(filename, sizeof(filename), "%s/small_%04d.txt", 
                 TEST_MOUNT_POINT, i);
        
        if (fs_unlink(filename) == 0) {
            delete_count++;
        }
    }
    
    end_time = k_uptime_get();
    printk("删除 %d 个小文件耗时: %lld ms\n", 
           delete_count, end_time - start_time);
    
    return 0;
}

/* 场景4：目录操作测试 */
static int test_directory_operations(void) {
    struct fs_dir_t dir;
    char dir_path[64];
    char subdir_path[64];
    int rc;
    int64_t start_time, end_time;
    
    printk("开始目录操作测试...\n");
    
    /* 测试1：创建和遍历目录 */
    start_time = k_uptime_get();
    
    // 创建嵌套目录
    for (int i = 0; i < 5; i++) {
        snprintf(dir_path, sizeof(dir_path), "%s/dir_level_%d", 
                 TEST_MOUNT_POINT, i);
        rc = fs_mkdir(dir_path);
        if (rc < 0 && rc != -EEXIST) {
            printk("创建目录失败 %s: %d\n", dir_path, rc);
        }
    }
    
    // 在最后一级目录创建文件
    snprintf(dir_path, sizeof(dir_path), "%s/dir_level_4", TEST_MOUNT_POINT);
    for (int i = 0; i < 10; i++) {
        snprintf(subdir_path, sizeof(subdir_path), 
                "%s/file_%d.txt", dir_path, i);
        struct fs_file_t file;
        fs_file_t_init(&file);
        rc = fs_open(&file, subdir_path, FS_O_CREATE | FS_O_WRITE);
        if (rc == 0) {
            fs_close(&file);
        }
    }
    
    /* 测试2：目录遍历性能 */
    fs_dir_t_init(&dir);
    rc = fs_opendir(&dir, TEST_MOUNT_POINT);
    if (rc < 0) {
        printk("无法打开目录: %d\n", rc);
        return rc;
    }
    
    int entry_count = 0;
    struct fs_dirent entry;
    
    while (1) {
        rc = fs_readdir(&dir, &entry);
        if (rc < 0 || entry.name[0] == 0) {
            break;
        }
        entry_count++;
    }
    
    fs_closedir(&dir);
    end_time = k_uptime_get();
    
    printk("目录遍历: %d 个条目, 耗时 %lld ms\n", 
           entry_count, end_time - start_time);
    
    /* 清理：删除测试目录 */
    for (int i = 4; i >= 0; i--) {
        snprintf(dir_path, sizeof(dir_path), "%s/dir_level_%d", 
                 TEST_MOUNT_POINT, i);
        
        // 先删除目录中的文件
        if (i == 4) {
            for (int j = 0; j < 10; j++) {
                snprintf(subdir_path, sizeof(subdir_path), 
                        "%s/file_%d.txt", dir_path, j);
                fs_unlink(subdir_path);
            }
        }
        
        fs_unlink(dir_path); // LittleFS 中删除目录使用 unlink
    }
    
    return 0;
}

/* 显示性能结果 */
static void display_performance_results(void) {
    printk("\n====== LittleFS 性能测试结果 ======\n");
    printk("存储设备: NOR Flash @ %s\n", TEST_MOUNT_POINT);
    printk("块大小: %d 字节\n", TEST_BLOCK_SIZE);
    printk("----------------------------------\n");
    printk("顺序写入: %llu us, %u KB/s\n", 
           stats.seq_write_time, stats.write_speed);
    printk("顺序读取: %llu us, %u KB/s\n", 
           stats.seq_read_time, stats.read_speed);
    printk("随机访问: %llu us/操作\n", stats.random_write_time);
    printk("总操作数: %u\n", stats.operations);
    printk("==================================\n");
}

/* 主测试函数 */
int main(void) {
    int rc;
    printk("\n***** LittleFS on NOR Flash Performance Test *****\n");
    print_fs_status();
    
    /* 运行测试场景 */
    printk("\n--- 场景1: 基础顺序读写 ---\n");
    rc = test_sequential_rw();
    if (rc != 0) {
        printk("顺序读写测试失败: %d\n", rc);
    }

#if 0
    printk("\n--- 场景2: 随机访问 ---\n");
    rc = test_random_access();
    if (rc != 0) {
        printk("随机访问测试失败: %d\n", rc);
    }
    
    printk("\n--- 场景3: 小文件操作 ---\n");
    rc = test_small_files();
    if (rc != 0) {
        printk("小文件测试失败: %d\n", rc);
    }
    
    printk("\n--- 场景4: 目录操作 ---\n");
    rc = test_directory_operations();
    if (rc != 0) {
        printk("目录操作测试失败: %d\n", rc);
    }
#endif

    /* 显示结果 */
    display_performance_results();

    return 0;
}
```
